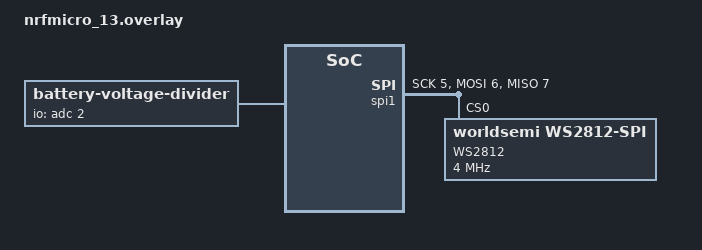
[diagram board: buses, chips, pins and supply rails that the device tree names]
#include <dt-bindings/led/led.h>

/ {
	chosen {
		zmk,underglow = &led_strip;
		zmk,battery = &vbatt;
	};
	vbatt: vbatt {
		compatible = "zmk,battery-voltage-divider";
		label = "BATTERY";
		io-channels = <&adc 2>;
		output-ohms = <2000000>;
		full-ohms = <(2000000 + 820000)>;
	};
};

&spi1 {
	compatible = "nordic,nrf-spim";
	status = "okay";
	mosi-pin = <6>;
	// Unused pins, needed for SPI definition, but not used by the ws2812 driver itself.
	sck-pin = <5>;
	miso-pin = <7>;

	led_strip: ws2812@0 {
		compatible = "worldsemi,ws2812-spi";
		label = "WS2812";

		/* SPI */
		reg = <0>; /* ignored, but necessary for SPI bindings */
		spi-max-frequency = <4000000>;

		/* WS2812 */
		chain-length = <11>; /* arbitrary; change at will */
		spi-one-frame = <0x70>;
		spi-zero-frame = <0x40>;
		color-mapping = <LED_COLOR_ID_GREEN LED_COLOR_ID_RED LED_COLOR_ID_BLUE>;
	};
};
